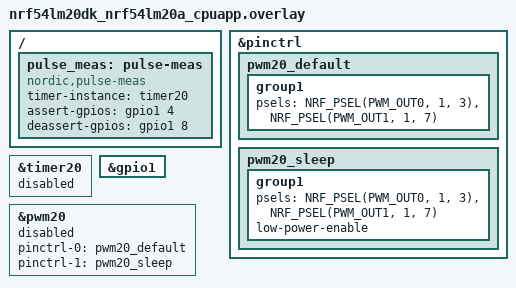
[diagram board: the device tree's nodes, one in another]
/*
 * Copyright (c) 2026 Nordic Semiconductor ASA
 *
 * SPDX-License-Identifier: LicenseRef-Nordic-5-Clause
 */

/*
 * Test requires Loopback between:
 *  - PWM20 OUT[0] at P1.03 <-> GPIO input at P1.04
 *  - PWM20 OUT[1] at P1.07 <-> GPIO input at P1.08
 */

&pinctrl {
	pwm20_default: pwm20_default {
		group1 {
			psels = <NRF_PSEL(PWM_OUT0, 1, 3)>,
				<NRF_PSEL(PWM_OUT1, 1, 7)>;
		};
	};

	pwm20_sleep: pwm20_sleep {
		group1 {
			psels = <NRF_PSEL(PWM_OUT0, 1, 3)>,
				<NRF_PSEL(PWM_OUT1, 1, 7)>;
			low-power-enable;
		};
	};
};

/ {
	pulse_meas: pulse-meas {
		compatible = "nordic,pulse-meas";
		status = "okay";
		timer-instance = <&timer20>;
		assert-gpios = <&gpio1 4 GPIO_ACTIVE_HIGH>;
		deassert-gpios = <&gpio1 8 GPIO_ACTIVE_HIGH>;
	};
};

&timer20 {
	status = "reserved";
};

&gpio1 {
	status = "okay";
};

tester_pwm: &pwm20 {
	status = "reserved";
	pinctrl-0 = <&pwm20_default>;
	pinctrl-1 = <&pwm20_sleep>;
	pinctrl-names = "default", "sleep";
};
